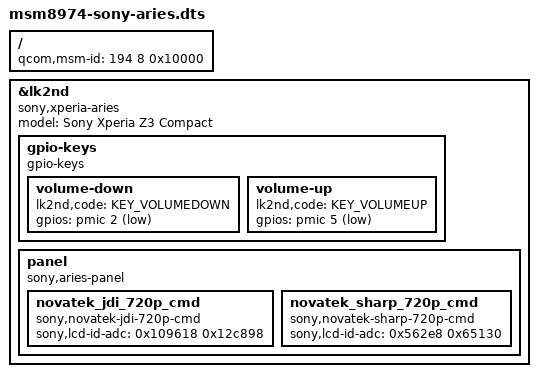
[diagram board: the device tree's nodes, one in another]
// SPDX-License-Identifier: GPL-2.0-only

/dts-v1/;

#include <skeleton32.dtsi>
#include <lk2nd.dtsi>

/ {
	qcom,msm-id = <194 8 0x10000>;
};

&lk2nd {
	model = "Sony Xperia Z3 Compact";
	compatible = "sony,xperia-aries";
	
	gpio-keys {
		compatible = "gpio-keys";
		
		volume-down {
			lk2nd,code = <KEY_VOLUMEDOWN>;
			gpios = <&pmic 2 (GPIO_ACTIVE_LOW | GPIO_PULL_UP)>;
		};
		
		volume-up {
			lk2nd,code = <KEY_VOLUMEUP>;
			gpios = <&pmic 5 (GPIO_ACTIVE_LOW | GPIO_PULL_UP)>;
		};
	};
	
	panel {
		compatible = "sony,aries-panel", "lk2nd,panel";
		
		novatek_jdi_720p_cmd {
			compatible = "sony,novatek-jdi-720p-cmd";
			sony,lcd-id-adc = <0x109618 0x12c898>;
		};
		
		novatek_sharp_720p_cmd {
			compatible = "sony,novatek-sharp-720p-cmd";
			sony,lcd-id-adc = <0x562e8 0x65130>;
		};
	};
};

#include "msm8974pro-ac-shinano_aries_display.dtsi"

